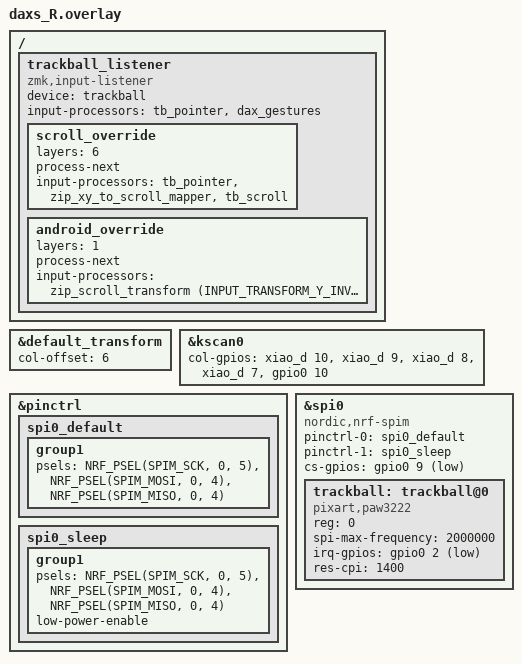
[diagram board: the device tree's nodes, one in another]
#include "daxs.dtsi"
#include <input/processors.dtsi>
#include <dt-bindings/zmk/input_transform.h>
#include <dt-bindings/zmk/keys.h>
#include "trackball_processors.dtsi"

&default_transform {
  col-offset = <6>;
};

&kscan0 {
  col-gpios
    = <&xiao_d 10 GPIO_ACTIVE_HIGH>  // D10/P1.15 -> Col0
    , <&xiao_d 9 GPIO_ACTIVE_HIGH>   // D9/P1.14 -> Col1
    , <&xiao_d 8 GPIO_ACTIVE_HIGH>   // D8/P1.13 -> Col2
    , <&xiao_d 7 GPIO_ACTIVE_HIGH>   // D7/P1.12 -> Col3
    , <&gpio0 10 GPIO_ACTIVE_HIGH>   // NFC2/P0.10 -> Col4
    ;
};

/ {
  trackball_listener {
    compatible = "zmk,input-listener";
    device = <&trackball>;
    // The gesture processor picks its profile by layer and stops the pointer by zeroing the
    // movement, so it needs no override of its own and works under the ones below.
    input-processors = <&tb_pointer>, <&dax_gestures>;

    scroll_override {
      layers = <6>;  // SCROLL layer
      process-next;
      input-processors
        = <&tb_pointer>
        , <&zip_xy_to_scroll_mapper>
        , <&tb_scroll>
        ;
    };

    // Declared last and with `process-next`: the Android layer is permanently active while its
    // BLE profile is selected, so it must neither shadow the Scroll override nor end the chain.
    // It only flips the wheel the Scroll override produced; X/Y pass through untouched.
    android_override {
      layers = <1>;  // ANDROID layer
      process-next;
      input-processors = <&zip_scroll_transform (INPUT_TRANSFORM_Y_INVERT)>;
    };
  };
};

&pinctrl {
  spi0_default: spi0_default {
    group1 {
      psels = <NRF_PSEL(SPIM_SCK, 0, 5)>,  // P0.05 (D5/SCLK)
        <NRF_PSEL(SPIM_MOSI, 0, 4)>,       // P0.04 (D4/SDIO)
        <NRF_PSEL(SPIM_MISO, 0, 4)>;       // P0.04 (D4/SDIO)
    };
  };

  spi0_sleep: spi0_sleep {
    group1 {
      psels = <NRF_PSEL(SPIM_SCK, 0, 5)>,
        <NRF_PSEL(SPIM_MOSI, 0, 4)>,
        <NRF_PSEL(SPIM_MISO, 0, 4)>;
      low-power-enable;
    };
  };
};

&spi0 {
  status = "okay";
  compatible = "nordic,nrf-spim";
  pinctrl-0 = <&spi0_default>;
  pinctrl-1 = <&spi0_sleep>;
  pinctrl-names = "default", "sleep";
  cs-gpios = <&gpio0 9 GPIO_ACTIVE_LOW>;  // NFC1/P0.09 (CS)

  trackball: trackball@0 {
    status = "okay";
    compatible = "pixart,paw3222";
    reg = <0>;
    spi-max-frequency = <2000000>;
    irq-gpios = <&gpio0 2 (GPIO_ACTIVE_LOW | GPIO_PULL_UP)>;  // P0.02 (D0/MOTION)
    res-cpi = <1400>;
  };
};
